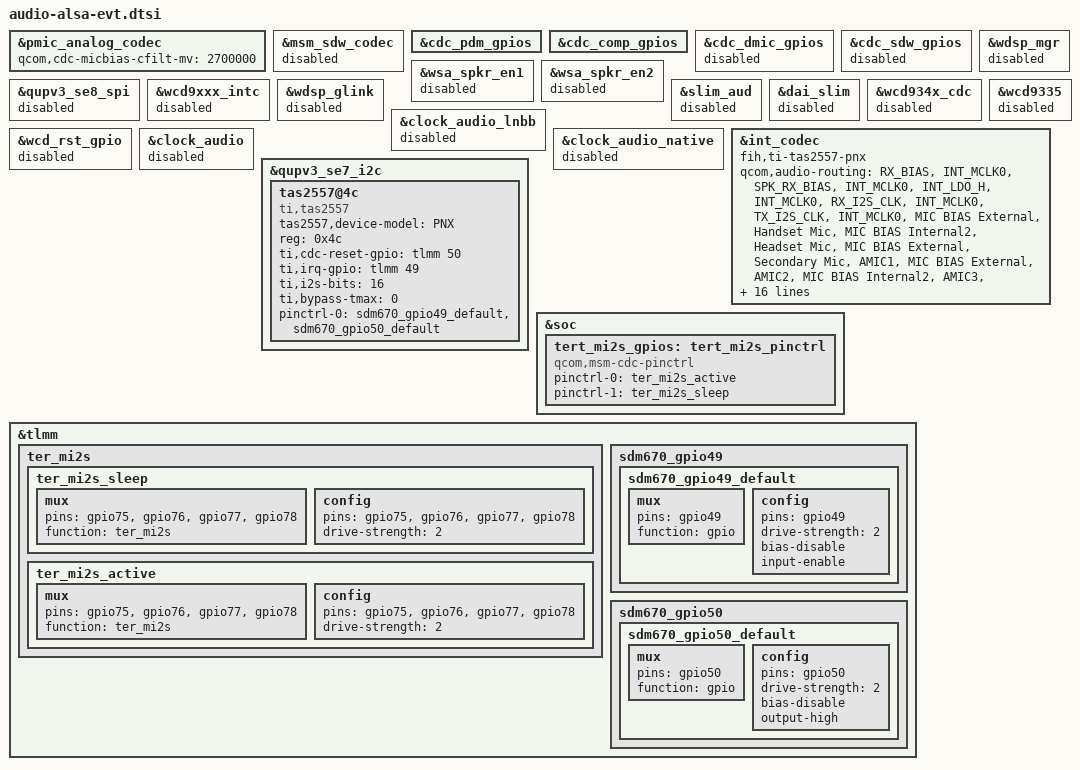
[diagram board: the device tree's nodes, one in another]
/* Copyright (c) 2017, The Linux Foundation. All rights reserved.
 *
 * This program is free software; you can redistribute it and/or modify
 * it under the terms of the GNU General Public License version 2 and
 * only version 2 as published by the Free Software Foundation.
 *
 * This program is distributed in the hope that it will be useful,
 * but WITHOUT ANY WARRANTY; without even the implied warranty of
 * MERCHANTABILITY or FITNESS FOR A PARTICULAR PURPOSE.  See the
 * GNU General Public License for more details.
 */

&pmic_analog_codec {
	status = "okay";
	/* support AKG headset */
	qcom,cdc-micbias-cfilt-mv = <2700000>;
};

&msm_sdw_codec {
	status = "disabled";
};

&cdc_pdm_gpios {
	status = "okay";
};

&cdc_comp_gpios {
	status = "okay";
};

&cdc_dmic_gpios {
	status = "disabled";
};

&cdc_sdw_gpios {
	status = "disabled";
};

&wsa_spkr_en1 {
	status = "disabled";
};

&wsa_spkr_en2 {
	status = "disabled";
};

&qupv3_se8_spi {
	status = "disabled";
};

&wcd9xxx_intc {
	status = "disabled";
};

&wdsp_mgr {
	status = "disabled";
};

&wdsp_glink {
	status = "disabled";
};

&slim_aud {
	status = "disabled";
};

&dai_slim {
	status = "disabled";
};

&wcd934x_cdc {
	status = "disabled";
};

&clock_audio_lnbb {
	status = "disabled";
};

&wcd_rst_gpio {
	status = "disabled";
};

&wcd9xxx_intc {
	status = "disabled";
};

&wcd9335 {
	status = "disabled";
};

&clock_audio {
	status = "disabled";
};

&clock_audio_native {
	status = "disabled";
};

&int_codec {
	status = "okay";
	fih,ti-tas2557-pnx;
	qcom,audio-routing =
		"RX_BIAS", "INT_MCLK0",
		"SPK_RX_BIAS", "INT_MCLK0",
		"INT_LDO_H", "INT_MCLK0",
		"RX_I2S_CLK", "INT_MCLK0",
		"TX_I2S_CLK", "INT_MCLK0",
		"MIC BIAS External", "Handset Mic",
		"MIC BIAS Internal2", "Headset Mic",
		"MIC BIAS External", "Secondary Mic",
		"AMIC1", "MIC BIAS External",
		"AMIC2", "MIC BIAS Internal2",
		"AMIC3", "MIC BIAS External",
		"MICBIAS_REGULATOR", "VDDA18_L10_REGULATOR",
		"VDDA18_L10_REGULATOR", "VDD_L1_REGULATOR",
		"PDM_IN_RX1", "PDM_OUT_RX1",
		"PDM_IN_RX2", "PDM_OUT_RX2",
		"PDM_IN_RX3", "PDM_OUT_RX3",
		"ADC1_IN", "ADC1_OUT",
		"ADC2_IN", "ADC2_OUT",
		"ADC3_IN", "ADC3_OUT";

	/delete-property/ qcom,cdc-dmic-gpios;
	qcom,msm-micbias1-ext-cap;
	/delete-property/ qcom,msm-micbias2-ext-cap;
	qcom,wsa-disable = <1>;
	qcom,msm-mbhc-hphl-swh = <1>;
	qcom,msm-mbhc-gnd-swh = <1>;
	qcom,tert-mi2s-gpios = <&tert_mi2s_gpios>;

	qcom,wsa-max-devs = <0>;
	/delete-property/ qcom,wsa-devs;
	/delete-property/ qcom,wsa-aux-dev-prefix;

	fih,msm-hs-v-headset-max = <1700>;
	fih,msm-btn-vol-thr-low = <100 230 380 380 380>;
	fih,msm-btn-vol-thr-high = <100 260 510 510 510>;
    fih,fih-mbhc-customized-debounce-supported = <9>;
};

/* TAS2557 SmartAmp I2C */
&qupv3_se7_i2c {
    status = "okay";
    tas2557@4c {
        compatible = "ti,tas2557";
        tas2557,device-model = "PNX";
        reg = <0x4c>;
        ti,cdc-reset-gpio = <&tlmm 50 0>;
        ti,irq-gpio = <&tlmm 49 0>;
        ti,i2s-bits = <16>;   /* support 16, 24, 32 */
        ti,bypass-tmax = <0>;   /* 0, not bypass; 1, bypass */
        pinctrl-names = "default";
        pinctrl-0 = <&sdm670_gpio49_default &sdm670_gpio50_default>;
    };
};

&soc{
	tert_mi2s_gpios: tert_mi2s_pinctrl {
		compatible = "qcom,msm-cdc-pinctrl";
		pinctrl-names = "aud_active", "aud_sleep";
		pinctrl-0 = <&ter_mi2s_active>;
		pinctrl-1 = <&ter_mi2s_sleep>;
	};
};


&tlmm{

	ter_mi2s {
		ter_mi2s_sleep: ter_mi2s_sleep {
			mux {
				pins = "gpio75", "gpio76" , "gpio77", "gpio78";
				function = "ter_mi2s";
			};
	
			config {
				pins = "gpio75", "gpio76" , "gpio77", "gpio78";
				drive-strength = <2>; /* 2 mA */
			};
		};
	
		ter_mi2s_active: ter_mi2s_active {
			mux {
				pins = "gpio75", "gpio76" , "gpio77", "gpio78";
				function = "ter_mi2s";
			};
			config {
				pins = "gpio75", "gpio76" , "gpio77", "gpio78";
				drive-strength = <2>; /* 8 mA */
			};
		};
	};

	sdm670_gpio49 { /* SAMP_IRQ */
		sdm670_gpio49_default: sdm670_gpio49_default {
			mux {
				pins = "gpio49";
				function = "gpio";
			};

			config {
				pins = "gpio49";
				drive-strength = <2>;
				bias-disable;
				input-enable;
			};
		};
	};
	sdm670_gpio50 { /* SAMP_RESET */
		sdm670_gpio50_default: sdm670_gpio50_default {
			mux {
				pins = "gpio50";
				function = "gpio";
			};

			config {
				pins = "gpio50";
				drive-strength = <2>;
				bias-disable;
				output-high;
			};
		};
	};

};


